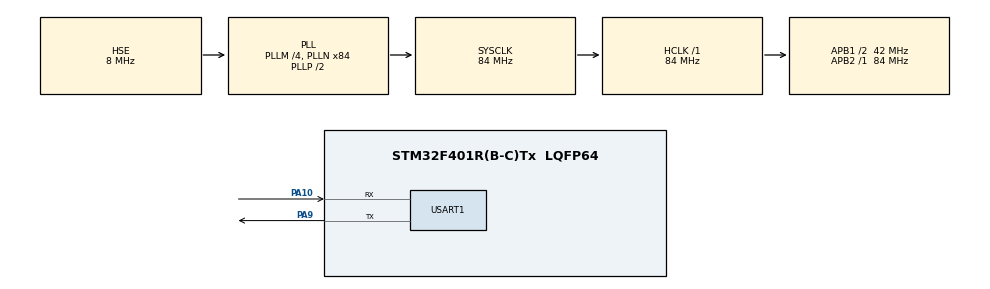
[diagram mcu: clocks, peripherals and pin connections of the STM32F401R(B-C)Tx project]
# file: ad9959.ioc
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Mcu.Family=STM32F4
Mcu.Name=STM32F401R(B-C)Tx
Mcu.Package=LQFP64
NVIC.PriorityGroup=NVIC_PRIORITYGROUP_4
PA10.Mode=Asynchronous
PA10.Signal=USART1_RX
PA9.Mode=Asynchronous
PA9.Signal=USART1_TX
PC14-OSC32_IN.Mode=LSE-External-Oscillator
PC14-OSC32_IN.Signal=RCC_OSC32_IN
PC15-OSC32_OUT.Mode=LSE-External-Oscillator
PC15-OSC32_OUT.Signal=RCC_OSC32_OUT
PH0\ -\ OSC_IN.Mode=HSE-External-Oscillator
PH0\ -\ OSC_IN.Signal=RCC_OSC_IN
PH1\ -\ OSC_OUT.Mode=HSE-External-Oscillator
PH1\ -\ OSC_OUT.Signal=RCC_OSC_OUT
ProjectManager.HeapSize=0x200
ProjectManager.StackSize=0x400
ProjectManager.TargetToolchain=Makefile
RCC.48MHZClocksFreq_Value=42000000
RCC.AHBFreq_Value=84000000
RCC.APB1CLKDivider=RCC_HCLK_DIV2
RCC.APB1Freq_Value=42000000
RCC.APB1TimFreq_Value=84000000
RCC.APB2Freq_Value=84000000
RCC.APB2TimFreq_Value=84000000
RCC.CortexFreq_Value=84000000
RCC.EnbaleCSS=true
RCC.HCLKFreq_Value=84000000
RCC.HSE_VALUE=8000000
RCC.HSI_VALUE=16000000
RCC.PLLM=4
RCC.PLLN=84
RCC.PLLSourceVirtual=RCC_PLLSOURCE_HSE
RCC.SYSCLKFreq_VALUE=84000000
RCC.SYSCLKSource=RCC_SYSCLKSOURCE_PLLCLK
RCC.VCOOutputFreq_Value=168000000
USART1.VirtualMode=VM_ASYNC
board=custom

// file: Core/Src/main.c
/* USER CODE BEGIN Header */
/**
 ******************************************************************************
 * @file           : main.c
 * @brief          : Main program body
 ******************************************************************************
 * @attention
 *
 * Copyright (c) 2023 STMicroelectronics.
 * All rights reserved.
 *
 * This software is licensed under terms that can be found in the LICENSE file
 * in the root directory of this software component.
 * If no LICENSE file comes with this software, it is provided AS-IS.
 *
 ******************************************************************************
 */
/* USER CODE END Header */
#include "main.h"
#include "usart.h"
#include "gpio.h"

void SystemClock_Config(void);

/* USER CODE BEGIN 0 */
int _write(int file, char *ptr, int len)
{
  HAL_UART_Transmit(&huart1, (const uint8_t *)ptr, len, HAL_MAX_DELAY);
  return len;
}

__STATIC_INLINE uint32_t GXT_SYSTICK_IsActiveCounterFlag(void)
{
  return ((SysTick->CTRL & SysTick_CTRL_COUNTFLAG_Msk) == (SysTick_CTRL_COUNTFLAG_Msk));
}
static uint32_t getCurrentMicros(void)
{
  /* Ensure COUNTFLAG is reset by reading SysTick control and status register */
  GXT_SYSTICK_IsActiveCounterFlag();
  uint32_t m = HAL_GetTick();
  const uint32_t tms = SysTick->LOAD + 1;
  __IO uint32_t u = tms - SysTick->VAL;
  if (GXT_SYSTICK_IsActiveCounterFlag())
  {
    m = HAL_GetTick();
    u = tms - SysTick->VAL;
  }
  return (m * 1000 + (u * 1000) / tms);
}
/* USER CODE END 0 */

int main(void)
{

  /* MCU Configuration--------------------------------------------------------*/

  /* Reset of all peripherals, Initializes the Flash interface and the Systick. */
  HAL_Init();

  /* Configure the system clock */
  SystemClock_Config();

  /* Initialize all configured peripherals */
  MX_GPIO_Init();
  MX_USART1_UART_Init();
  /* USER CODE BEGIN 2 */

  printf("Hello World.\n");

  /* USER CODE END 2 */

  /* Infinite loop */
  while (1)
  {

  }
}

void SystemClock_Config(void)
{
  RCC_OscInitTypeDef RCC_OscInitStruct = {0};
  RCC_ClkInitTypeDef RCC_ClkInitStruct = {0};

  /** Configure the main internal regulator output voltage
   */
  __HAL_RCC_PWR_CLK_ENABLE();
  __HAL_PWR_VOLTAGESCALING_CONFIG(PWR_REGULATOR_VOLTAGE_SCALE2);

  /** Initializes the RCC Oscillators according to the specified parameters
   * in the RCC_OscInitTypeDef structure.
   */
  RCC_OscInitStruct.OscillatorType = RCC_OSCILLATORTYPE_HSE;
  RCC_OscInitStruct.HSEState = RCC_HSE_ON;
  RCC_OscInitStruct.PLL.PLLState = RCC_PLL_ON;
  RCC_OscInitStruct.PLL.PLLSource = RCC_PLLSOURCE_HSE;
  RCC_OscInitStruct.PLL.PLLM = 4;
  RCC_OscInitStruct.PLL.PLLN = 84;
  RCC_OscInitStruct.PLL.PLLP = RCC_PLLP_DIV2;
  RCC_OscInitStruct.PLL.PLLQ = 4;
  if (HAL_RCC_OscConfig(&RCC_OscInitStruct) != HAL_OK)
  {
    Error_Handler();
  }

  /** Initializes the CPU, AHB and APB buses clocks
   */
  RCC_ClkInitStruct.ClockType = RCC_CLOCKTYPE_HCLK | RCC_CLOCKTYPE_SYSCLK | RCC_CLOCKTYPE_PCLK1 | RCC_CLOCKTYPE_PCLK2;
  RCC_ClkInitStruct.SYSCLKSource = RCC_SYSCLKSOURCE_PLLCLK;
  RCC_ClkInitStruct.AHBCLKDivider = RCC_SYSCLK_DIV1;
  RCC_ClkInitStruct.APB1CLKDivider = RCC_HCLK_DIV2;
  RCC_ClkInitStruct.APB2CLKDivider = RCC_HCLK_DIV1;

  if (HAL_RCC_ClockConfig(&RCC_ClkInitStruct, FLASH_LATENCY_2) != HAL_OK)
  {
    Error_Handler();
  }

  /** Enables the Clock Security System
   */
  HAL_RCC_EnableCSS();
}

void Error_Handler(void)
{
  __disable_irq();
  while (1)
  {
  }
}
